AUTOSAR XML (schema 4-2-2)
package /STELLANTIS/EPT/ASWCs
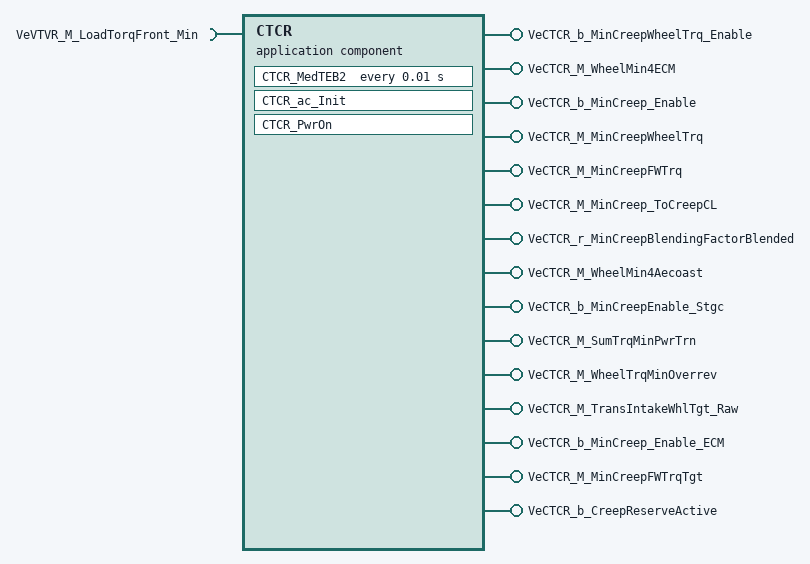
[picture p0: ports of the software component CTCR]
  application sw component type CTCR
    require port VeVTVR_M_LoadTorqFront_Min: variation-point={short-label=vpVeVTVR_M_LoadTorqFront_Min, sw-syscond=1}, nonqueued-receiver-com-spec{data-element=Value, init-value=0}, required-interface=VeVTVR_M_LoadTorqFront_Min
    15 x provide port, all with nonqueued-sender-com-spec{data-element=Value, init-value=0}:
      VeCTCR_b_MinCreepWheelTrq_Enable: provided-interface=VeCTCR_b_MinCreepWheelTrq_Enable
      VeCTCR_M_WheelMin4ECM: provided-interface=VeCTCR_M_WheelMin4ECM
      VeCTCR_b_MinCreep_Enable: provided-interface=VeCTCR_b_MinCreep_Enable
      VeCTCR_M_MinCreepWheelTrq: provided-interface=VeCTCR_M_MinCreepWheelTrq
      VeCTCR_M_MinCreepFWTrq: provided-interface=VeCTCR_M_MinCreepFWTrq
      VeCTCR_M_MinCreep_ToCreepCL: provided-interface=VeCTCR_M_MinCreep_ToCreepCL
      VeCTCR_r_MinCreepBlendingFactorBlended: provided-interface=VeCTCR_r_MinCreepBlendingFactorBlended
      VeCTCR_M_WheelMin4Aecoast: provided-interface=VeCTCR_M_WheelMin4Aecoast
      VeCTCR_b_MinCreepEnable_Stgc: provided-interface=VeCTCR_b_MinCreepEnable_Stgc
      VeCTCR_M_SumTrqMinPwrTrn: provided-interface=VeCTCR_M_SumTrqMinPwrTrn
      VeCTCR_M_WheelTrqMinOverrev: provided-interface=VeCTCR_M_WheelTrqMinOverrev
      VeCTCR_M_TransIntakeWhlTgt_Raw: provided-interface=VeCTCR_M_TransIntakeWhlTgt_Raw
      VeCTCR_b_MinCreep_Enable_ECM: provided-interface=VeCTCR_b_MinCreep_Enable_ECM
      VeCTCR_M_MinCreepFWTrqTgt: provided-interface=VeCTCR_M_MinCreepFWTrqTgt
      VeCTCR_b_CreepReserveActive: provided-interface=VeCTCR_b_CreepReserveActive
    behavior IB_CTCR: data-type-mapping=msADTtoIDTMapping, handle-termination-and-restart=NO-SUPPORT
      timing event Event_MedTEB2: start-on-event=CTCR_MedTEB2, period=0.01
      init event Event_CTCR_ac_Init: start-on-event=CTCR_ac_Init
      init event Event_PwrOn: start-on-event=CTCR_PwrOn
      explicit-inter-runnable-variables:
        5 x data, all with category=VALUE, sw-calibration-access=READ-ONLY, init-value=0:
          VeCTCR_b_MinCreep_Enable_FUNC_IRV: type=Boolean
          VeCTCR_M_MinCreepWheelTrqBlend_FUNC_IRV: type=Float
          VeCTCR_M_MinCreepWheelTrq_FUNC_IRV: type=Float
          VeCTCR_b_MinCreep_Enable_ECM_FUNC_IRV: type=Boolean
          VeCTCR_M_WheelMin4ECM_FUNC_IRV_IRV: type=Float
      runnable CTCR_ac_Init
      runnable CTCR_PwrOn
        data-send-points:
          15 x access:
            OUT_VeCTCR_M_MinCreepWheelTrq_Value: accessed-variable=VeCTCR_M_MinCreepWheelTrq.Value
            OUT_VeCTCR_b_MinCreepWheelTrq_Enable_Value: accessed-variable=VeCTCR_b_MinCreepWheelTrq_Enable.Value
            OUT_VeCTCR_M_MinCreepFWTrq_Value: accessed-variable=VeCTCR_M_MinCreepFWTrq.Value
            OUT_VeCTCR_M_MinCreep_ToCreepCL_Value: accessed-variable=VeCTCR_M_MinCreep_ToCreepCL.Value
            OUT_VeCTCR_M_WheelMin4ECM_Value: accessed-variable=VeCTCR_M_WheelMin4ECM.Value
            OUT_VeCTCR_b_MinCreep_Enable_Value: accessed-variable=VeCTCR_b_MinCreep_Enable.Value
            OUT_VeCTCR_r_MinCreepBlendingFactorBlended_Value: accessed-variable=VeCTCR_r_MinCreepBlendingFactorBlended.Value
            OUT_VeCTCR_M_WheelMin4Aecoast_Value: accessed-variable=VeCTCR_M_WheelMin4Aecoast.Value
            OUT_VeCTCR_b_MinCreepEnable_Stgc_Value: accessed-variable=VeCTCR_b_MinCreepEnable_Stgc.Value
            OUT_VeCTCR_M_SumTrqMinPwrTrn_Value: accessed-variable=VeCTCR_M_SumTrqMinPwrTrn.Value
            OUT_VeCTCR_M_WheelTrqMinOverrev_Value: accessed-variable=VeCTCR_M_WheelTrqMinOverrev.Value
            OUT_VeCTCR_M_TransIntakeWhlTgt_Raw_Value: accessed-variable=VeCTCR_M_TransIntakeWhlTgt_Raw.Value
            OUT_VeCTCR_b_MinCreep_Enable_ECM_Value: accessed-variable=VeCTCR_b_MinCreep_Enable_ECM.Value
            OUT_VeCTCR_M_MinCreepFWTrqTgt_Value: accessed-variable=VeCTCR_M_MinCreepFWTrqTgt.Value
            OUT_VeCTCR_b_CreepReserveActive_Value: accessed-variable=VeCTCR_b_CreepReserveActive.Value
        written-local-variables:
          5 x access:
            WV_VeCTCR_M_MinCreepWheelTrqBlend_FUNC_IRV: accessed-variable=VeCTCR_M_MinCreepWheelTrqBlend_FUNC_IRV
            WV_VeCTCR_M_WheelMin4ECM_FUNC_IRV_IRV: accessed-variable=VeCTCR_M_WheelMin4ECM_FUNC_IRV_IRV
            WV_VeCTCR_b_MinCreep_Enable_ECM_FUNC_IRV: accessed-variable=VeCTCR_b_MinCreep_Enable_ECM_FUNC_IRV
            WV_VeCTCR_M_MinCreepWheelTrq_FUNC_IRV: accessed-variable=VeCTCR_M_MinCreepWheelTrq_FUNC_IRV
            WV_VeCTCR_b_MinCreep_Enable_FUNC_IRV: accessed-variable=VeCTCR_b_MinCreep_Enable_FUNC_IRV
      runnable CTCR_MedTEB2
        data-receive-point-by-arguments:
          access IN_VeVTVR_M_LoadTorqFront_Min_Value: accessed-variable=VeVTVR_M_LoadTorqFront_Min.Value, variation-point={short-label=vpIN_VeVTVR_M_LoadTorqFront_Min_Value, sw-syscond=1}
        data-send-points:
          14 x access:
            OUT_VeCTCR_M_MinCreepWheelTrq_Value: accessed-variable=VeCTCR_M_MinCreepWheelTrq.Value
            OUT_VeCTCR_b_MinCreep_Enable_ECM_Value: accessed-variable=VeCTCR_b_MinCreep_Enable_ECM.Value
            OUT_VeCTCR_M_MinCreepFWTrq_Value: accessed-variable=VeCTCR_M_MinCreepFWTrq.Value
            OUT_VeCTCR_M_MinCreep_ToCreepCL_Value: accessed-variable=VeCTCR_M_MinCreep_ToCreepCL.Value
            OUT_VeCTCR_M_WheelMin4ECM_Value: accessed-variable=VeCTCR_M_WheelMin4ECM.Value
            OUT_VeCTCR_b_MinCreep_Enable_Value: accessed-variable=VeCTCR_b_MinCreep_Enable.Value
            OUT_VeCTCR_r_MinCreepBlendingFactorBlended_Value: accessed-variable=VeCTCR_r_MinCreepBlendingFactorBlended.Value
            OUT_VeCTCR_M_WheelMin4Aecoast_Value: accessed-variable=VeCTCR_M_WheelMin4Aecoast.Value
            OUT_VeCTCR_b_MinCreepEnable_Stgc_Value: accessed-variable=VeCTCR_b_MinCreepEnable_Stgc.Value
            OUT_VeCTCR_M_SumTrqMinPwrTrn_Value: accessed-variable=VeCTCR_M_SumTrqMinPwrTrn.Value
            OUT_VeCTCR_M_WheelTrqMinOverrev_Value: accessed-variable=VeCTCR_M_WheelTrqMinOverrev.Value
            OUT_VeCTCR_M_TransIntakeWhlTgt_Raw_Value: accessed-variable=VeCTCR_M_TransIntakeWhlTgt_Raw.Value
            OUT_VeCTCR_M_MinCreepFWTrqTgt_Value: accessed-variable=VeCTCR_M_MinCreepFWTrqTgt.Value
            OUT_VeCTCR_b_CreepReserveActive_Value: accessed-variable=VeCTCR_b_CreepReserveActive.Value
      4 x variation point proxy, all with category=CONDITION, condition-access=0:
        Variant_CTCR_FUNC
        Variant_CTCR_PxPy
        Variant_CTCR_RTC_Imp_On
        Variant_CTCR_RTC_Turb_On
